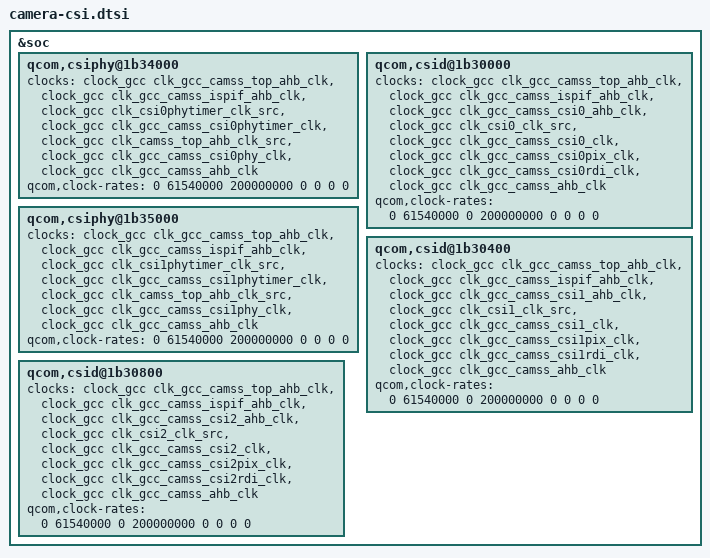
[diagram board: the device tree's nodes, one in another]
/*
 * Copyright (c) 2015-2017, The Linux Foundation. All rights reserved.
 *
 * This program is free software; you can redistribute it and/or modify
 * it under the terms of the GNU General Public License version 2 and
 * only version 2 as published by the Free Software Foundation.
 *
 * This program is distributed in the hope that it will be useful,
 * but WITHOUT ANY WARRANTY; without even the implied warranty of
 * MERCHANTABILITY or FITNESS FOR A PARTICULAR PURPOSE.  See the
 * GNU General Public License for more details.
 */

&soc {
	qcom,csiphy@1b34000 {
		clocks = <&clock_gcc clk_gcc_camss_top_ahb_clk>,
			<&clock_gcc clk_gcc_camss_ispif_ahb_clk>,
			<&clock_gcc clk_csi0phytimer_clk_src>,
			<&clock_gcc clk_gcc_camss_csi0phytimer_clk>,
			<&clock_gcc clk_camss_top_ahb_clk_src>,
			<&clock_gcc clk_gcc_camss_csi0phy_clk>,
			<&clock_gcc clk_gcc_camss_ahb_clk>;
		clock-names = "camss_top_ahb_clk", "ispif_ahb_clk",
			"csiphy_timer_src_clk", "csiphy_timer_clk",
			"camss_ahb_src", "csi_phy_clk",
			"camss_ahb_clk";
		qcom,clock-rates = <0 61540000 200000000 0 0 0 0>;
	};

	qcom,csiphy@1b35000 {
		clocks = <&clock_gcc clk_gcc_camss_top_ahb_clk>,
			<&clock_gcc clk_gcc_camss_ispif_ahb_clk>,
			<&clock_gcc clk_csi1phytimer_clk_src>,
			<&clock_gcc clk_gcc_camss_csi1phytimer_clk>,
			<&clock_gcc clk_camss_top_ahb_clk_src>,
			<&clock_gcc clk_gcc_camss_csi1phy_clk>,
			<&clock_gcc clk_gcc_camss_ahb_clk>;
		clock-names = "camss_top_ahb_clk", "ispif_ahb_clk",
			"csiphy_timer_src_clk", "csiphy_timer_clk",
			"camss_ahb_src", "csi_phy_clk",
			"camss_ahb_clk";
		qcom,clock-rates = <0 61540000 200000000 0 0 0 0>;
	};

	qcom,csid@1b30000 {
		clocks = <&clock_gcc clk_gcc_camss_top_ahb_clk>,
			<&clock_gcc clk_gcc_camss_ispif_ahb_clk>,
			<&clock_gcc clk_gcc_camss_csi0_ahb_clk>,
			<&clock_gcc clk_csi0_clk_src>,
			<&clock_gcc clk_gcc_camss_csi0_clk>,
			<&clock_gcc clk_gcc_camss_csi0pix_clk>,
			<&clock_gcc clk_gcc_camss_csi0rdi_clk>,
			<&clock_gcc clk_gcc_camss_ahb_clk>;
		clock-names = "camss_top_ahb_clk",
			"ispif_ahb_clk", "csi_ahb_clk", "csi_src_clk",
			"csi_clk",  "csi_pix_clk",
			"csi_rdi_clk", "camss_ahb_clk";
		qcom,clock-rates = <0 61540000 0 200000000 0 0 0 0>;
	};

	qcom,csid@1b30400 {
		clocks = <&clock_gcc clk_gcc_camss_top_ahb_clk>,
			<&clock_gcc clk_gcc_camss_ispif_ahb_clk>,
			<&clock_gcc clk_gcc_camss_csi1_ahb_clk>,
			<&clock_gcc clk_csi1_clk_src>,
			<&clock_gcc clk_gcc_camss_csi1_clk>,
			<&clock_gcc clk_gcc_camss_csi1pix_clk>,
			<&clock_gcc clk_gcc_camss_csi1rdi_clk>,
			<&clock_gcc clk_gcc_camss_ahb_clk>;
		clock-names = "camss_top_ahb_clk",
			"ispif_ahb_clk", "csi_ahb_clk", "csi_src_clk",
			"csi_clk", "csi_pix_clk",
			"csi_rdi_clk", "camss_ahb_clk";
		qcom,clock-rates = <0 61540000 0 200000000 0 0 0 0>;
	};

	qcom,csid@1b30800 {
		clocks = <&clock_gcc clk_gcc_camss_top_ahb_clk>,
			<&clock_gcc clk_gcc_camss_ispif_ahb_clk>,
			<&clock_gcc clk_gcc_camss_csi2_ahb_clk>,
			<&clock_gcc clk_csi2_clk_src>,
			<&clock_gcc clk_gcc_camss_csi2_clk>,
			<&clock_gcc clk_gcc_camss_csi2pix_clk>,
			<&clock_gcc clk_gcc_camss_csi2rdi_clk>,
			<&clock_gcc clk_gcc_camss_ahb_clk>;
		clock-names = "camss_top_ahb_clk",
			"ispif_ahb_clk", "csi_ahb_clk", "csi_src_clk",
			"csi_clk", "csi_pix_clk",
			"csi_rdi_clk", "camss_ahb_clk";
		qcom,clock-rates = <0 61540000 0 200000000 0 0 0 0>;
	};
};
